VERSION ""

NS_ :

BS_:

BU_: BMS VCU

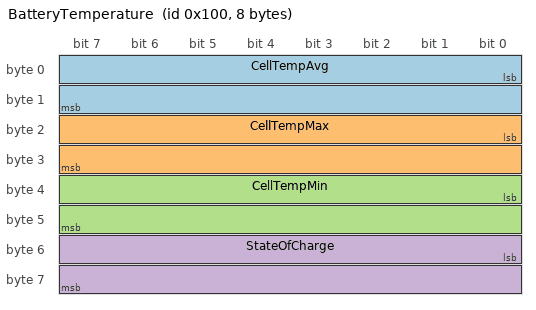
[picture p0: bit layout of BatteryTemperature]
BO_ 256 BatteryTemperature: 8 BMS
 SG_ CellTempAvg : 0|16@1+ (0.5,-40) [-40|125] "degC" VCU
 SG_ CellTempMax : 16|16@1+ (0.5,-40) [-40|125] "degC" VCU
 SG_ CellTempMin : 32|16@1+ (0.5,-40) [-40|125] "degC" VCU
 SG_ StateOfCharge : 48|16@1+ (0.5,0) [0|100] "%" VCU

CM_ BU_ BMS "Battery Management System";
CM_ BU_ VCU "Vehicle Control Unit";
CM_ BO_ 256 "Battery temperature data frame sent at 10Hz";
CM_ SG_ 256 CellTempAvg "Average cell temperature across pack";
CM_ SG_ 256 CellTempMax "Maximum cell temperature (hottest cell)";
CM_ SG_ 256 CellTempMin "Minimum cell temperature (coldest cell)";
CM_ SG_ 256 StateOfCharge "Battery state of charge percentage";

BA_DEF_ BO_ "GenMsgCycleTime" INT 0 10000;
BA_DEF_DEF_ "GenMsgCycleTime" 100;
